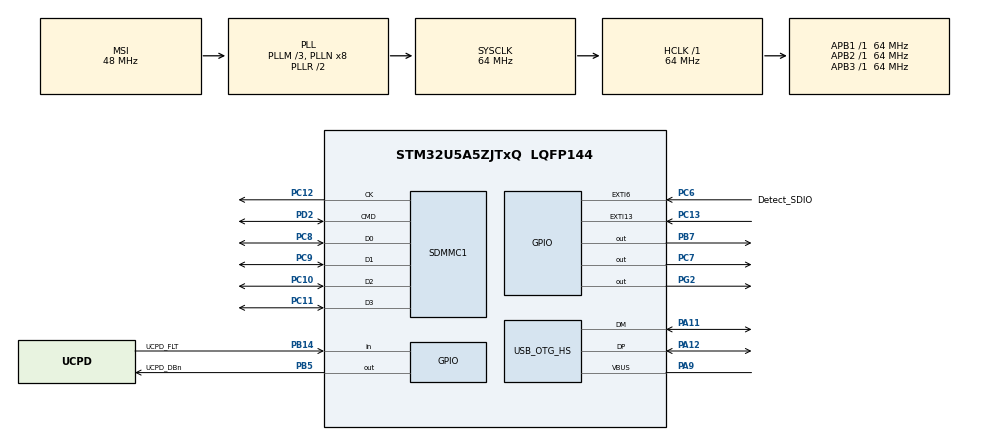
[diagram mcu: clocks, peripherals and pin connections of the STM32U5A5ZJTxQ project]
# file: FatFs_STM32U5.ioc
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CORTEX_M33_NS.userName=CORTEX_M33
Mcu.Family=STM32U5
Mcu.Name=STM32U5A5ZJTxQ
Mcu.Package=LQFP144
NUCLEO-U5A5ZJ-Q.BUTTON=1
NUCLEO-U5A5ZJ-Q.LD1=true
NUCLEO-U5A5ZJ-Q.LD2=true
NUCLEO-U5A5ZJ-Q.LD3=true
NUCLEO-U5A5ZJ-Q.VCP=true
NVIC.EXTI13_IRQn=true\:0\:0\:false\:false\:true\:false\:true\:true
NVIC.PriorityGroup=NVIC_PRIORITYGROUP_4
NVIC.SDMMC1_IRQn=true\:0\:0\:false\:false\:true\:true\:true\:true
PA10.Signal=USART1_RX
PA11.Mode=Internal_Phy_Host
PA11.Signal=USB_OTG_HS_DM
PA12.Mode=Internal_Phy_Host
PA12.Signal=USB_OTG_HS_DP
PA13\ (JTMS/SWDIO).Mode=Trace_Asynchronous_SW
PA13\ (JTMS/SWDIO).Signal=DEBUG_JTMS-SWDIO
PA14\ (JTCK/SWCLK).Mode=Trace_Asynchronous_SW
PA14\ (JTCK/SWCLK).Signal=DEBUG_JTCK-SWCLK
PA15\ (JTDI).Signal=UCPD1_CC1
PA9.Mode=Activate_VBUS_FS
PA9.Signal=USB_OTG_HS_VBUS
PB14.GPIO_Label=UCPD_FLT
PB14.Signal=GPIO_Input
PB15.Signal=UCPD1_CC2
PB3\ (JTDO/TRACESWO).Mode=Trace_Asynchronous_SW
PB3\ (JTDO/TRACESWO).Signal=DEBUG_JTDO-SWO
PB5.GPIO_Label=UCPD_DBn
PB5.Signal=GPIO_Output
PB7.Signal=GPIO_Output
PC10.Mode=SD_4_bits_Wide_bus
PC10.Signal=SDMMC1_D2
PC11.Mode=SD_4_bits_Wide_bus
PC11.Signal=SDMMC1_D3
PC12.Mode=SD_4_bits_Wide_bus
PC12.Signal=SDMMC1_CK
PC13.Signal=GPXTI13
PC14-OSC32_IN\ (PC14).Mode=LSE-External-Oscillator
PC14-OSC32_IN\ (PC14).Signal=RCC_OSC32_IN
PC15-OSC32_OUT\ (PC15).Mode=LSE-External-Oscillator
PC15-OSC32_OUT\ (PC15).Signal=RCC_OSC32_OUT
PC2.GPIO_Label=VBUS_SENSE
PC2.Signal=ADC1_IN3
PC6.GPIO_Label=Detect_SDIO
PC6.Signal=GPXTI6
PC7.Signal=GPIO_Output
PC8.Mode=SD_4_bits_Wide_bus
PC8.Signal=SDMMC1_D0
PC9.Mode=SD_4_bits_Wide_bus
PC9.Signal=SDMMC1_D1
PD2.Mode=SD_4_bits_Wide_bus
PD2.Signal=SDMMC1_CMD
PG2.Signal=GPIO_Output
PH0-OSC_IN\ (PH0).Mode=HSE-External-Oscillator
PH0-OSC_IN\ (PH0).Signal=RCC_OSC_IN
PH1-OSC_OUT\ (PH1).Mode=HSE-External-Oscillator
PH1-OSC_OUT\ (PH1).Signal=RCC_OSC_OUT
PWR.PowerMode=PWR_SMPS_SUPPLY
PWR.pwrPrivilege=PWR_PRIVILEGE_YES
ProjectManager.HeapSize=0x2000
ProjectManager.StackSize=0x4000
ProjectManager.TargetToolchain=STM32CubeIDE
RCC.ADCFreq_Value=16000000
RCC.AHBFreq_Value=64000000
RCC.APB1Freq_Value=64000000
RCC.APB1TimFreq_Value=64000000
RCC.APB2Freq_Value=64000000
RCC.APB2TimFreq_Value=64000000
RCC.APB3Freq_Value=64000000
RCC.CortexFreq_Value=64000000
RCC.DACCLockSelectionVirtual=RCC_DAC1CLKSOURCE_LSI
RCC.EPOD_VALUE=48000000
RCC.HCLKFreq_Value=64000000
RCC.HSE_VALUE=16000000
RCC.HSI48_VALUE=48000000
RCC.HSI_VALUE=16000000
RCC.LSIDIV_VALUE=32000
RCC.MSIClockRange=RCC_MSIRANGE_0
RCC.MSI_VALUE=48000000
RCC.PLL1P=8
RCC.PLLFRACN=0
RCC.PLLM=3
RCC.PLLN=8
RCC.SYSCLKFreq_VALUE=64000000
RCC.SYSCLKSource=RCC_SYSCLKSOURCE_PLLCLK
RCC.VCOOutputFreq_Value=128000000
USB_OTG_HS.VirtualMode=Host_HS
VP_ICACHE_VS_ICACHE.Mode=DirectMappedCache
VP_LPBAMQUEUE_VS_QUEUE.Mode=QUEUEMODE
VP_MEMORYMAP_VS_MEMORYMAP.Mode=CurAppReg
VP_NUCLEO-U5A5ZJ-Q_VS_BSP_COMMON.Mode=COMMON
VP_PWR_VS_DBSignals.Mode=DisableDeadBatterySignals
VP_PWR_VS_LPOM.Mode=PowerOptimisation
VP_PWR_VS_SECSignals.Mode=Security/Privilege
board=NUCLEO-U5A5ZJ-Q

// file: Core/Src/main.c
/* USER CODE BEGIN Header */
/**
  ******************************************************************************
  * @file           : main.c
  * @brief          : Main program body
  ******************************************************************************
  * @attention
  *
  * Copyright (c) 2024 STMicroelectronics.
  * All rights reserved.
  *
  * This software is licensed under terms that can be found in the LICENSE file
  * in the root directory of this software component.
  * If no LICENSE file comes with this software, it is provided AS-IS.
  *
  ******************************************************************************
  */
/* USER CODE END Header */
#include "main.h"
#include "stm32u5xx_nucleo.h"
#include <stdio.h>

/* USER CODE BEGIN Includes */
#include "fatfs.h"

/* USER CODE END Includes */

SD_HandleTypeDef hsd1;

HCD_HandleTypeDef hhcd_USB_OTG_HS;

COM_InitTypeDef BspCOMInit;

void SystemClock_Config(void);
static void SystemPower_Config(void);
static void MX_GPIO_Init(void);
static void MX_ICACHE_Init(void);
static void MX_SDMMC1_SD_Init(void);
static void MX_USB_OTG_HS_HCD_Init(void);

int main(void)
{

  /* MCU Configuration--------------------------------------------------------*/

  /* Reset of all peripherals, Initializes the Flash interface and the Systick. */
  HAL_Init();

  /* Configure the system clock */
  SystemClock_Config();

  /* Configure the System Power */
  SystemPower_Config();

  /* Initialize all configured peripherals */
  MX_GPIO_Init();
  MX_ICACHE_Init();
  MX_SDMMC1_SD_Init();
  MX_USB_OTG_HS_HCD_Init();
  /* USER CODE BEGIN 2 */
  MX_FATFS_Init();

  /* USER CODE END 2 */

  /* Initialize leds */
  BSP_LED_Init(LED_GREEN);
  BSP_LED_Init(LED_RED);
  BSP_LED_Init(LED_BLUE);

  /* Initialize USER push-button, will be used to trigger an interrupt each time it's pressed.*/
  BSP_PB_Init(BUTTON_USER, BUTTON_MODE_EXTI);

  /* Initialize COM1 port (115200, 8 bits (7-bit data + 1 stop bit), no parity */
  BspCOMInit.BaudRate   = 115200;
  BspCOMInit.WordLength = COM_WORDLENGTH_8B;
  BspCOMInit.StopBits   = COM_STOPBITS_1;
  BspCOMInit.Parity     = COM_PARITY_NONE;
  BspCOMInit.HwFlowCtl  = COM_HWCONTROL_NONE;
  if (BSP_COM_Init(COM1, &BspCOMInit) != BSP_ERROR_NONE)
  {
    Error_Handler();
  }

  /* Infinite loop */
  while (1)
  {

  }
}

void SystemClock_Config(void)
{
  RCC_OscInitTypeDef RCC_OscInitStruct = {0};
  RCC_ClkInitTypeDef RCC_ClkInitStruct = {0};

  /** Configure the main internal regulator output voltage
  */
  if (HAL_PWREx_ControlVoltageScaling(PWR_REGULATOR_VOLTAGE_SCALE2) != HAL_OK)
  {
    Error_Handler();
  }

  /** Initializes the CPU, AHB and APB buses clocks
  */
  RCC_OscInitStruct.OscillatorType = RCC_OSCILLATORTYPE_MSI;
  RCC_OscInitStruct.MSIState = RCC_MSI_ON;
  RCC_OscInitStruct.MSICalibrationValue = RCC_MSICALIBRATION_DEFAULT;
  RCC_OscInitStruct.MSIClockRange = RCC_MSIRANGE_0;
  RCC_OscInitStruct.PLL.PLLState = RCC_PLL_ON;
  RCC_OscInitStruct.PLL.PLLSource = RCC_PLLSOURCE_MSI;
  RCC_OscInitStruct.PLL.PLLMBOOST = RCC_PLLMBOOST_DIV4;
  RCC_OscInitStruct.PLL.PLLM = 3;
  RCC_OscInitStruct.PLL.PLLN = 8;
  RCC_OscInitStruct.PLL.PLLP = 8;
  RCC_OscInitStruct.PLL.PLLQ = 2;
  RCC_OscInitStruct.PLL.PLLR = 2;
  RCC_OscInitStruct.PLL.PLLRGE = RCC_PLLVCIRANGE_1;
  RCC_OscInitStruct.PLL.PLLFRACN = 0;
  if (HAL_RCC_OscConfig(&RCC_OscInitStruct) != HAL_OK)
  {
    Error_Handler();
  }

  /** Initializes the CPU, AHB and APB buses clocks
  */
  RCC_ClkInitStruct.ClockType = RCC_CLOCKTYPE_HCLK|RCC_CLOCKTYPE_SYSCLK
                              |RCC_CLOCKTYPE_PCLK1|RCC_CLOCKTYPE_PCLK2
                              |RCC_CLOCKTYPE_PCLK3;
  RCC_ClkInitStruct.SYSCLKSource = RCC_SYSCLKSOURCE_PLLCLK;
  RCC_ClkInitStruct.AHBCLKDivider = RCC_SYSCLK_DIV1;
  RCC_ClkInitStruct.APB1CLKDivider = RCC_HCLK_DIV1;
  RCC_ClkInitStruct.APB2CLKDivider = RCC_HCLK_DIV1;
  RCC_ClkInitStruct.APB3CLKDivider = RCC_HCLK_DIV1;

  if (HAL_RCC_ClockConfig(&RCC_ClkInitStruct, FLASH_LATENCY_2) != HAL_OK)
  {
    Error_Handler();
  }
}

/**
  * @brief Power Configuration
  * @retval None
  */
static void SystemPower_Config(void)
{

  /*
   * Disable the internal Pull-Up in Dead Battery pins of UCPD peripheral
   */
  HAL_PWREx_DisableUCPDDeadBattery();

  /*
   * Switch to SMPS regulator instead of LDO
   */
  if (HAL_PWREx_ConfigSupply(PWR_SMPS_SUPPLY) != HAL_OK)
  {
    Error_Handler();
  }

  /*
   * PWR Privilege Configuration
   */
  HAL_PWR_ConfigAttributes(PWR_ALL, PWR_NSEC_PRIV);
}

static void MX_ICACHE_Init(void)
{

  /** Enable instruction cache in 1-way (direct mapped cache)
  */
  if (HAL_ICACHE_ConfigAssociativityMode(ICACHE_1WAY) != HAL_OK)
  {
    Error_Handler();
  }
  if (HAL_ICACHE_Enable() != HAL_OK)
  {
    Error_Handler();
  }

}

static void MX_SDMMC1_SD_Init(void)
{

  hsd1.Instance = SDMMC1;
  hsd1.Init.ClockEdge = SDMMC_CLOCK_EDGE_RISING;
  hsd1.Init.ClockPowerSave = SDMMC_CLOCK_POWER_SAVE_DISABLE;
  hsd1.Init.BusWide = SDMMC_BUS_WIDE_4B;
  hsd1.Init.HardwareFlowControl = SDMMC_HARDWARE_FLOW_CONTROL_DISABLE;
  hsd1.Init.ClockDiv = 0;
  if (HAL_SD_Init(&hsd1) != HAL_OK)
  {
    Error_Handler();
  }

}

static void MX_USB_OTG_HS_HCD_Init(void)
{

  hhcd_USB_OTG_HS.Instance = USB_OTG_HS;
  hhcd_USB_OTG_HS.Init.Host_channels = 16;
  hhcd_USB_OTG_HS.Init.speed = HCD_SPEED_HIGH;
  hhcd_USB_OTG_HS.Init.dma_enable = DISABLE;
  hhcd_USB_OTG_HS.Init.phy_itface = USB_OTG_HS_EMBEDDED_PHY;
  hhcd_USB_OTG_HS.Init.Sof_enable = DISABLE;
  hhcd_USB_OTG_HS.Init.low_power_enable = DISABLE;
  hhcd_USB_OTG_HS.Init.use_external_vbus = ENABLE;
  if (HAL_HCD_Init(&hhcd_USB_OTG_HS) != HAL_OK)
  {
    Error_Handler();
  }

}

static void MX_GPIO_Init(void)
{
  GPIO_InitTypeDef GPIO_InitStruct = {0};

  /* GPIO Ports Clock Enable */
  __HAL_RCC_GPIOC_CLK_ENABLE();
  __HAL_RCC_GPIOH_CLK_ENABLE();
  __HAL_RCC_GPIOB_CLK_ENABLE();
  __HAL_RCC_GPIOA_CLK_ENABLE();
  __HAL_RCC_GPIOD_CLK_ENABLE();

  /*Configure GPIO pin Output Level */
  HAL_GPIO_WritePin(UCPD_DBn_GPIO_Port, UCPD_DBn_Pin, GPIO_PIN_RESET);

  /*Configure GPIO pin : VBUS_SENSE_Pin */
  GPIO_InitStruct.Pin = VBUS_SENSE_Pin;
  GPIO_InitStruct.Mode = GPIO_MODE_ANALOG;
  GPIO_InitStruct.Pull = GPIO_NOPULL;
  HAL_GPIO_Init(VBUS_SENSE_GPIO_Port, &GPIO_InitStruct);

  /*Configure GPIO pin : UCPD_FLT_Pin */
  GPIO_InitStruct.Pin = UCPD_FLT_Pin;
  GPIO_InitStruct.Mode = GPIO_MODE_INPUT;
  GPIO_InitStruct.Pull = GPIO_NOPULL;
  HAL_GPIO_Init(UCPD_FLT_GPIO_Port, &GPIO_InitStruct);

  /*Configure GPIO pin : PB15 */
  GPIO_InitStruct.Pin = GPIO_PIN_15;
  GPIO_InitStruct.Mode = GPIO_MODE_ANALOG;
  GPIO_InitStruct.Pull = GPIO_NOPULL;
  HAL_GPIO_Init(GPIOB, &GPIO_InitStruct);

  /*Configure GPIO pin : Detect_SDIO_Pin */
  GPIO_InitStruct.Pin = Detect_SDIO_Pin;
  GPIO_InitStruct.Mode = GPIO_MODE_IT_RISING;
  GPIO_InitStruct.Pull = GPIO_NOPULL;
  HAL_GPIO_Init(Detect_SDIO_GPIO_Port, &GPIO_InitStruct);

  /*Configure GPIO pin : PA15 */
  GPIO_InitStruct.Pin = GPIO_PIN_15;
  GPIO_InitStruct.Mode = GPIO_MODE_ANALOG;
  GPIO_InitStruct.Pull = GPIO_NOPULL;
  HAL_GPIO_Init(GPIOA, &GPIO_InitStruct);

  /*Configure GPIO pin : UCPD_DBn_Pin */
  GPIO_InitStruct.Pin = UCPD_DBn_Pin;
  GPIO_InitStruct.Mode = GPIO_MODE_OUTPUT_PP;
  GPIO_InitStruct.Pull = GPIO_NOPULL;
  GPIO_InitStruct.Speed = GPIO_SPEED_FREQ_LOW;
  HAL_GPIO_Init(UCPD_DBn_GPIO_Port, &GPIO_InitStruct);

  /* EXTI interrupt init*/
  HAL_NVIC_SetPriority(EXTI13_IRQn, 0, 0);
  HAL_NVIC_EnableIRQ(EXTI13_IRQn);

}

void Error_Handler(void)
{
  __disable_irq();
  while (1)
  {
  }
}
